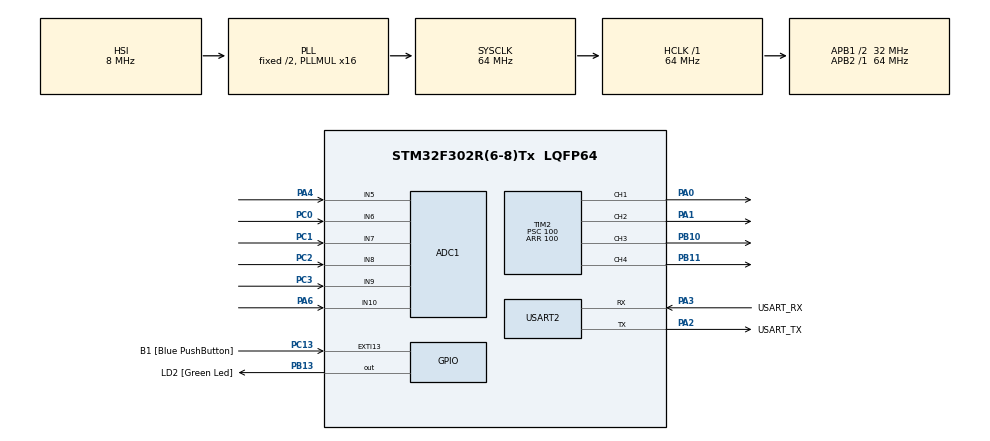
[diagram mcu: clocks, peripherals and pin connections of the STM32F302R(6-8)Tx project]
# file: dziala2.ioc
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ADC1.Channel-0\#ChannelRegularConversion=ADC_CHANNEL_5
ADC1.Channel-1\#ChannelRegularConversion=ADC_CHANNEL_6
ADC1.Channel-2\#ChannelRegularConversion=ADC_CHANNEL_7
ADC1.Channel-3\#ChannelRegularConversion=ADC_CHANNEL_8
ADC1.Channel-4\#ChannelRegularConversion=ADC_CHANNEL_8
ADC1.Channel-6\#ChannelRegularConversion=ADC_CHANNEL_9
ADC1.ContinuousConvMode=ENABLE
ADC1.DMAContinuousRequests=ENABLE
ADC1.InjNumberOfConversion=0
ADC1.NbrOfConversion=6
ADC1.NbrOfConversionFlag=1
ADC1.Offset-0\#ChannelRegularConversion=0
ADC1.Offset-1\#ChannelRegularConversion=0
ADC1.Offset-2\#ChannelRegularConversion=0
ADC1.Offset-3\#ChannelRegularConversion=0
ADC1.Offset-4\#ChannelRegularConversion=0
ADC1.Offset-6\#ChannelRegularConversion=0
ADC1.OffsetNumber-0\#ChannelRegularConversion=ADC_OFFSET_NONE
ADC1.OffsetNumber-1\#ChannelRegularConversion=ADC_OFFSET_NONE
ADC1.OffsetNumber-2\#ChannelRegularConversion=ADC_OFFSET_NONE
ADC1.OffsetNumber-3\#ChannelRegularConversion=ADC_OFFSET_NONE
ADC1.OffsetNumber-4\#ChannelRegularConversion=ADC_OFFSET_NONE
ADC1.OffsetNumber-6\#ChannelRegularConversion=ADC_OFFSET_NONE
ADC1.Rank-0\#ChannelRegularConversion=1
ADC1.Rank-1\#ChannelRegularConversion=2
ADC1.Rank-2\#ChannelRegularConversion=3
ADC1.Rank-3\#ChannelRegularConversion=4
ADC1.Rank-4\#ChannelRegularConversion=5
ADC1.Rank-6\#ChannelRegularConversion=6
ADC1.SamplingTime-0\#ChannelRegularConversion=ADC_SAMPLETIME_181CYCLES_5
ADC1.SamplingTime-1\#ChannelRegularConversion=ADC_SAMPLETIME_181CYCLES_5
ADC1.SamplingTime-2\#ChannelRegularConversion=ADC_SAMPLETIME_181CYCLES_5
ADC1.SamplingTime-3\#ChannelRegularConversion=ADC_SAMPLETIME_181CYCLES_5
ADC1.SamplingTime-4\#ChannelRegularConversion=ADC_SAMPLETIME_181CYCLES_5
ADC1.SamplingTime-6\#ChannelRegularConversion=ADC_SAMPLETIME_61CYCLES_5
ADC1.SubFamily=STM32F302x8
ADC1.master=1
Dma.ADC1.0.Direction=DMA_PERIPH_TO_MEMORY
Dma.ADC1.0.Instance=DMA1_Channel1
Dma.ADC1.0.MemDataAlignment=DMA_MDATAALIGN_HALFWORD
Dma.ADC1.0.MemInc=DMA_MINC_ENABLE
Dma.ADC1.0.Mode=DMA_CIRCULAR
Dma.ADC1.0.PeriphDataAlignment=DMA_PDATAALIGN_HALFWORD
Dma.ADC1.0.PeriphInc=DMA_PINC_DISABLE
Dma.ADC1.0.Priority=DMA_PRIORITY_LOW
Dma.Request0=ADC1
Mcu.Family=STM32F3
Mcu.Name=STM32F302R(6-8)Tx
Mcu.Package=LQFP64
NVIC.DMA1_Channel1_IRQn=true\:0\:0\:false\:false\:true\:false\:true
NVIC.PriorityGroup=NVIC_PRIORITYGROUP_0
PA0.Signal=S_TIM2_CH1_ETR
PA1.Signal=S_TIM2_CH2
PA13.GPIO_Label=TMS
PA13.Mode=Serial_Wire
PA13.Signal=SYS_JTMS-SWDIO
PA14.GPIO_Label=TCK
PA14.Mode=Serial_Wire
PA14.Signal=SYS_JTCK-SWCLK
PA2.GPIO_Label=USART_TX
PA2.GPIO_Mode=GPIO_MODE_AF_PP
PA2.GPIO_PuPd=GPIO_NOPULL
PA2.GPIO_Speed=GPIO_SPEED_FREQ_LOW
PA2.Mode=Asynchronous
PA2.Signal=USART2_TX
PA3.GPIO_Label=USART_RX
PA3.GPIO_Mode=GPIO_MODE_AF_PP
PA3.GPIO_PuPd=GPIO_NOPULL
PA3.GPIO_Speed=GPIO_SPEED_FREQ_LOW
PA3.Mode=Asynchronous
PA3.Signal=USART2_RX
PA4.Mode=IN5-Single-Ended
PA4.Signal=ADC1_IN5
PA6.Signal=ADCx_IN10
PB10.Signal=S_TIM2_CH3
PB11.Signal=S_TIM2_CH4
PB13.GPIO_Label=LD2 [Green Led]
PB13.Signal=GPIO_Output
PB3.GPIO_Label=SWO
PB3.Mode=Trace_Asynchronous_SW
PB3.Signal=SYS_JTDO-TRACESWO
PC0.Signal=ADCx_IN6
PC1.Signal=ADCx_IN7
PC13.GPIO_Label=B1 [Blue PushButton]
PC13.GPIO_ModeDefaultEXTI=GPIO_MODE_IT_FALLING
PC13.Signal=GPXTI13
PC14\ -\ OSC32_IN.Mode=LSE-External-Oscillator
PC14\ -\ OSC32_IN.Signal=RCC_OSC32_IN
PC15\ -\ OSC32_OUT.Mode=LSE-External-Oscillator
PC15\ -\ OSC32_OUT.Signal=RCC_OSC32_OUT
PC2.Signal=ADCx_IN8
PC3.Signal=ADCx_IN9
PF0-OSC_IN.Mode=HSE-External-Clock-Source
PF0-OSC_IN.Signal=RCC_OSC_IN
PF1-OSC_OUT.Signal=RCC_OSC_OUT
ProjectManager.HeapSize=0x200
ProjectManager.StackSize=0x400
ProjectManager.TargetToolchain=STM32CubeIDE
RCC.AHBFreq_Value=64000000
RCC.APB1CLKDivider=RCC_HCLK_DIV2
RCC.APB1Freq_Value=32000000
RCC.APB1TimFreq_Value=64000000
RCC.APB2Freq_Value=64000000
RCC.APB2TimFreq_Value=64000000
RCC.CortexFreq_Value=64000000
RCC.HCLKFreq_Value=64000000
RCC.HSE_VALUE=8000000
RCC.HSI_VALUE=8000000
RCC.PLLM=8
RCC.PLLMUL=RCC_PLL_MUL16
RCC.PLLN=336
RCC.PLLP=RCC_PLLP_DIV4
RCC.PLLQ=7
RCC.RCC_PLLsource_Clock_Source_FROM_HSE=RCC_HSE_PREDIV_DIV2
RCC.SYSCLKFreq_VALUE=64000000
RCC.SYSCLKSourceVirtual=RCC_SYSCLKSOURCE_PLLCLK
RCC.USBFreq_Value=64000000
SH.ADCx_IN10.0=ADC1_IN10,IN10-Single-Ended
SH.ADCx_IN6.0=ADC1_IN6,IN6-Single-Ended
SH.ADCx_IN7.0=ADC1_IN7,IN7-Single-Ended
SH.ADCx_IN8.0=ADC1_IN8,IN8-Single-Ended
SH.ADCx_IN9.0=ADC1_IN9,IN9-Single-Ended
SH.S_TIM2_CH1_ETR.0=TIM2_CH1,PWM Generation1 CH1
SH.S_TIM2_CH2.0=TIM2_CH2,PWM Generation2 CH2
SH.S_TIM2_CH3.0=TIM2_CH3,PWM Generation3 CH3
SH.S_TIM2_CH4.0=TIM2_CH4,PWM Generation4 CH4
TIM2.Channel-PWM\ Generation1\ CH1=TIM_CHANNEL_1
TIM2.Channel-PWM\ Generation2\ CH2=TIM_CHANNEL_2
TIM2.Channel-PWM\ Generation3\ CH3=TIM_CHANNEL_3
TIM2.Channel-PWM\ Generation4\ CH4=TIM_CHANNEL_4
TIM2.ClockDivision=TIM_CLOCKDIVISION_DIV2
TIM2.Period=100
TIM2.Prescaler=100
USART2.VirtualMode-Asynchronous=VM_ASYNC
VP_TIM2_VS_ClockSourceINT.Mode=Internal
board=NUCLEO-F302R8

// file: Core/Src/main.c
/* USER CODE BEGIN Header */
/**
  ******************************************************************************
  * @file           : main.c
  * @brief          : Main program body
  ******************************************************************************
  * @attention
  *
  * <h2><center>&copy; Copyright (c) 2020 STMicroelectronics.
  * All rights reserved.</center></h2>
  *
  * This software component is licensed by ST under BSD 3-Clause license,
  * the "License"; You may not use this file except in compliance with the
  * License. You may obtain a copy of the License at:
  *                        opensource.org/licenses/BSD-3-Clause
  *
  ******************************************************************************
  */
/* USER CODE END Header */

#include "main.h"

ADC_HandleTypeDef hadc1;
DMA_HandleTypeDef hdma_adc1;

TIM_HandleTypeDef htim2;

UART_HandleTypeDef huart2;

/* USER CODE BEGIN PV */
uint32_t v[6];
/* USER CODE END PV */

void SystemClock_Config(void);
static void MX_GPIO_Init(void);
static void MX_DMA_Init(void);
static void MX_ADC1_Init(void);
static void MX_TIM2_Init(void);
static void MX_USART2_UART_Init(void);

int main(void)
{

  /* MCU Configuration--------------------------------------------------------*/

  /* Reset of all peripherals, Initializes the Flash interface and the Systick. */
  HAL_Init();

  /* Configure the system clock */
  SystemClock_Config();

  /* Initialize all configured peripherals */
  MX_GPIO_Init();
  MX_DMA_Init();
  MX_ADC1_Init();
  MX_TIM2_Init();
  MX_USART2_UART_Init();
  /* USER CODE BEGIN 2 */
  HAL_TIM_PWM_Start(&htim2, TIM_CHANNEL_1);
  HAL_TIM_PWM_Start(&htim2, TIM_CHANNEL_2);
  HAL_TIM_PWM_Start(&htim2, TIM_CHANNEL_3);
  HAL_TIM_PWM_Start(&htim2, TIM_CHANNEL_4);
  HAL_ADC_Start_DMA(&hadc1, (uint32_t*)v, 6);
  HAL_ADC_Start_IT(&hadc1);
  /* USER CODE END 2 */

  /* Infinite loop */
  /* USER CODE BEGIN WHILE */
  while (1)

  {
	 HAL_ADC_Start_IT(&hadc1);

	 if((v[1]!=0) && (v[2]!=0))
	 {

		 TIM2->CCR1=20;
		 TIM2->CCR4=100;
	 }
	 else
	 {
		 TIM2->CCR1=100;
		 TIM2->CCR4=20;

	 }

    /* USER CODE END WHILE */

  }
}

void SystemClock_Config(void)
{
  RCC_OscInitTypeDef RCC_OscInitStruct = {0};
  RCC_ClkInitTypeDef RCC_ClkInitStruct = {0};
  RCC_PeriphCLKInitTypeDef PeriphClkInit = {0};

  /** Initializes the CPU, AHB and APB busses clocks
  */
  RCC_OscInitStruct.OscillatorType = RCC_OSCILLATORTYPE_HSI;
  RCC_OscInitStruct.HSIState = RCC_HSI_ON;
  RCC_OscInitStruct.HSICalibrationValue = RCC_HSICALIBRATION_DEFAULT;
  RCC_OscInitStruct.PLL.PLLState = RCC_PLL_ON;
  RCC_OscInitStruct.PLL.PLLSource = RCC_PLLSOURCE_HSI;
  RCC_OscInitStruct.PLL.PLLMUL = RCC_PLL_MUL16;
  if (HAL_RCC_OscConfig(&RCC_OscInitStruct) != HAL_OK)
  {
    Error_Handler();
  }
  /** Initializes the CPU, AHB and APB busses clocks
  */
  RCC_ClkInitStruct.ClockType = RCC_CLOCKTYPE_HCLK|RCC_CLOCKTYPE_SYSCLK
                              |RCC_CLOCKTYPE_PCLK1|RCC_CLOCKTYPE_PCLK2;
  RCC_ClkInitStruct.SYSCLKSource = RCC_SYSCLKSOURCE_PLLCLK;
  RCC_ClkInitStruct.AHBCLKDivider = RCC_SYSCLK_DIV1;
  RCC_ClkInitStruct.APB1CLKDivider = RCC_HCLK_DIV2;
  RCC_ClkInitStruct.APB2CLKDivider = RCC_HCLK_DIV1;

  if (HAL_RCC_ClockConfig(&RCC_ClkInitStruct, FLASH_LATENCY_2) != HAL_OK)
  {
    Error_Handler();
  }
  PeriphClkInit.PeriphClockSelection = RCC_PERIPHCLK_ADC1;
  PeriphClkInit.Adc1ClockSelection = RCC_ADC1PLLCLK_DIV1;

  if (HAL_RCCEx_PeriphCLKConfig(&PeriphClkInit) != HAL_OK)
  {
    Error_Handler();
  }
}

static void MX_ADC1_Init(void)
{

  ADC_ChannelConfTypeDef sConfig = {0};

  /** Common config
  */
  hadc1.Instance = ADC1;
  hadc1.Init.ClockPrescaler = ADC_CLOCK_ASYNC_DIV1;
  hadc1.Init.Resolution = ADC_RESOLUTION_12B;
  hadc1.Init.ScanConvMode = ADC_SCAN_ENABLE;
  hadc1.Init.ContinuousConvMode = ENABLE;
  hadc1.Init.DiscontinuousConvMode = DISABLE;
  hadc1.Init.ExternalTrigConvEdge = ADC_EXTERNALTRIGCONVEDGE_NONE;
  hadc1.Init.ExternalTrigConv = ADC_SOFTWARE_START;
  hadc1.Init.DataAlign = ADC_DATAALIGN_RIGHT;
  hadc1.Init.NbrOfConversion = 6;
  hadc1.Init.DMAContinuousRequests = ENABLE;
  hadc1.Init.EOCSelection = ADC_EOC_SINGLE_CONV;
  hadc1.Init.LowPowerAutoWait = DISABLE;
  hadc1.Init.Overrun = ADC_OVR_DATA_OVERWRITTEN;
  if (HAL_ADC_Init(&hadc1) != HAL_OK)
  {
    Error_Handler();
  }
  /** Configure Regular Channel
  */
  sConfig.Channel = ADC_CHANNEL_5;
  sConfig.Rank = ADC_REGULAR_RANK_1;
  sConfig.SingleDiff = ADC_SINGLE_ENDED;
  sConfig.SamplingTime = ADC_SAMPLETIME_181CYCLES_5;
  sConfig.OffsetNumber = ADC_OFFSET_NONE;
  sConfig.Offset = 0;
  if (HAL_ADC_ConfigChannel(&hadc1, &sConfig) != HAL_OK)
  {
    Error_Handler();
  }
  /** Configure Regular Channel
  */
  sConfig.Channel = ADC_CHANNEL_6;
  sConfig.Rank = ADC_REGULAR_RANK_2;
  if (HAL_ADC_ConfigChannel(&hadc1, &sConfig) != HAL_OK)
  {
    Error_Handler();
  }
  /** Configure Regular Channel
  */
  sConfig.Channel = ADC_CHANNEL_7;
  sConfig.Rank = ADC_REGULAR_RANK_3;
  if (HAL_ADC_ConfigChannel(&hadc1, &sConfig) != HAL_OK)
  {
    Error_Handler();
  }
  /** Configure Regular Channel
  */
  sConfig.Channel = ADC_CHANNEL_8;
  sConfig.Rank = ADC_REGULAR_RANK_4;
  if (HAL_ADC_ConfigChannel(&hadc1, &sConfig) != HAL_OK)
  {
    Error_Handler();
  }
  /** Configure Regular Channel
  */
  sConfig.Rank = ADC_REGULAR_RANK_5;
  if (HAL_ADC_ConfigChannel(&hadc1, &sConfig) != HAL_OK)
  {
    Error_Handler();
  }
  /** Configure Regular Channel
  */
  sConfig.Channel = ADC_CHANNEL_9;
  sConfig.Rank = ADC_REGULAR_RANK_6;
  sConfig.SamplingTime = ADC_SAMPLETIME_61CYCLES_5;
  if (HAL_ADC_ConfigChannel(&hadc1, &sConfig) != HAL_OK)
  {
    Error_Handler();
  }

}

static void MX_TIM2_Init(void)
{

  TIM_ClockConfigTypeDef sClockSourceConfig = {0};
  TIM_MasterConfigTypeDef sMasterConfig = {0};
  TIM_OC_InitTypeDef sConfigOC = {0};

  htim2.Instance = TIM2;
  htim2.Init.Prescaler = 100;
  htim2.Init.CounterMode = TIM_COUNTERMODE_UP;
  htim2.Init.Period = 100;
  htim2.Init.ClockDivision = TIM_CLOCKDIVISION_DIV2;
  htim2.Init.AutoReloadPreload = TIM_AUTORELOAD_PRELOAD_DISABLE;
  if (HAL_TIM_Base_Init(&htim2) != HAL_OK)
  {
    Error_Handler();
  }
  sClockSourceConfig.ClockSource = TIM_CLOCKSOURCE_INTERNAL;
  if (HAL_TIM_ConfigClockSource(&htim2, &sClockSourceConfig) != HAL_OK)
  {
    Error_Handler();
  }
  if (HAL_TIM_PWM_Init(&htim2) != HAL_OK)
  {
    Error_Handler();
  }
  sMasterConfig.MasterOutputTrigger = TIM_TRGO_RESET;
  sMasterConfig.MasterSlaveMode = TIM_MASTERSLAVEMODE_DISABLE;
  if (HAL_TIMEx_MasterConfigSynchronization(&htim2, &sMasterConfig) != HAL_OK)
  {
    Error_Handler();
  }
  sConfigOC.OCMode = TIM_OCMODE_PWM1;
  sConfigOC.Pulse = 0;
  sConfigOC.OCPolarity = TIM_OCPOLARITY_HIGH;
  sConfigOC.OCFastMode = TIM_OCFAST_DISABLE;
  if (HAL_TIM_PWM_ConfigChannel(&htim2, &sConfigOC, TIM_CHANNEL_1) != HAL_OK)
  {
    Error_Handler();
  }
  if (HAL_TIM_PWM_ConfigChannel(&htim2, &sConfigOC, TIM_CHANNEL_2) != HAL_OK)
  {
    Error_Handler();
  }
  if (HAL_TIM_PWM_ConfigChannel(&htim2, &sConfigOC, TIM_CHANNEL_3) != HAL_OK)
  {
    Error_Handler();
  }
  if (HAL_TIM_PWM_ConfigChannel(&htim2, &sConfigOC, TIM_CHANNEL_4) != HAL_OK)
  {
    Error_Handler();
  }
  HAL_TIM_MspPostInit(&htim2);

}

static void MX_USART2_UART_Init(void)
{

  huart2.Instance = USART2;
  huart2.Init.BaudRate = 38400;
  huart2.Init.WordLength = UART_WORDLENGTH_8B;
  huart2.Init.StopBits = UART_STOPBITS_1;
  huart2.Init.Parity = UART_PARITY_NONE;
  huart2.Init.Mode = UART_MODE_TX_RX;
  huart2.Init.HwFlowCtl = UART_HWCONTROL_NONE;
  huart2.Init.OverSampling = UART_OVERSAMPLING_16;
  huart2.Init.OneBitSampling = UART_ONE_BIT_SAMPLE_DISABLE;
  huart2.AdvancedInit.AdvFeatureInit = UART_ADVFEATURE_NO_INIT;
  if (HAL_UART_Init(&huart2) != HAL_OK)
  {
    Error_Handler();
  }

}

static void MX_DMA_Init(void)
{

  /* DMA controller clock enable */
  __HAL_RCC_DMA1_CLK_ENABLE();

  /* DMA interrupt init */
  /* DMA1_Channel1_IRQn interrupt configuration */
  HAL_NVIC_SetPriority(DMA1_Channel1_IRQn, 0, 0);
  HAL_NVIC_EnableIRQ(DMA1_Channel1_IRQn);

}

static void MX_GPIO_Init(void)
{
  GPIO_InitTypeDef GPIO_InitStruct = {0};

  /* GPIO Ports Clock Enable */
  __HAL_RCC_GPIOC_CLK_ENABLE();
  __HAL_RCC_GPIOF_CLK_ENABLE();
  __HAL_RCC_GPIOA_CLK_ENABLE();
  __HAL_RCC_GPIOB_CLK_ENABLE();

  /*Configure GPIO pin Output Level */
  HAL_GPIO_WritePin(LD2_GPIO_Port, LD2_Pin, GPIO_PIN_RESET);

  /*Configure GPIO pin : B1_Pin */
  GPIO_InitStruct.Pin = B1_Pin;
  GPIO_InitStruct.Mode = GPIO_MODE_IT_FALLING;
  GPIO_InitStruct.Pull = GPIO_NOPULL;
  HAL_GPIO_Init(B1_GPIO_Port, &GPIO_InitStruct);

  /*Configure GPIO pin : LD2_Pin */
  GPIO_InitStruct.Pin = LD2_Pin;
  GPIO_InitStruct.Mode = GPIO_MODE_OUTPUT_PP;
  GPIO_InitStruct.Pull = GPIO_NOPULL;
  GPIO_InitStruct.Speed = GPIO_SPEED_FREQ_LOW;
  HAL_GPIO_Init(LD2_GPIO_Port, &GPIO_InitStruct);

}

void Error_Handler(void)
{
}

/************************ (C) COPYRIGHT STMicroelectronics *****END OF FILE****/
